# STM32WB55_CM4 register map
File version: 2.0
CPU: CM4 r0p1, little endian, MPU, FPU, 4 interrupt priority bits
Registers are 32-bit, read-write, reset 0x0 unless marked. A register's access mark holds for its fields unless they carry their own. Offsets are from the block's base; [hi:lo] are bit positions; {n}, {i} and the like mark numbered series.

## CRS — Clock recovery system
Base 0x40006000
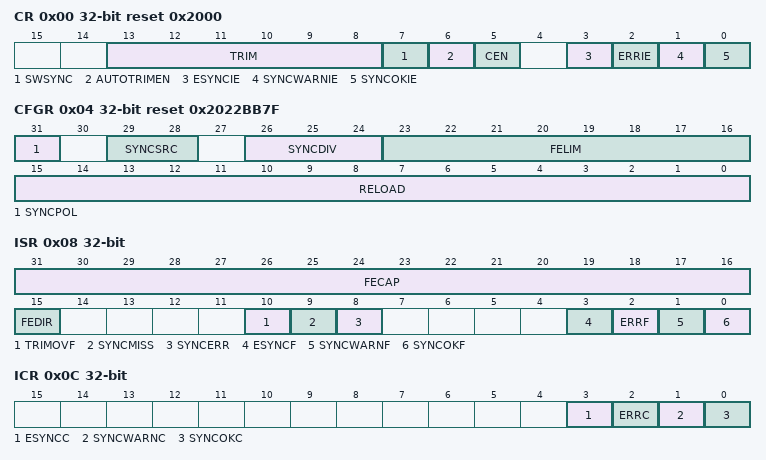
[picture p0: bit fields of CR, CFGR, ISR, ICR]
0x00 CR reset 0x2000 — CRS control register
  [13:8] TRIM — HSI48 oscillator smooth trimming
  [7] SWSYNC — Automatic trimming enable
  [6] AUTOTRIMEN — Automatic trimming enable
  [5] CEN — Frequency error counter enable
  [3] ESYNCIE — Expected SYNC interrupt enable
  [2] ERRIE — Synchronization or trimming error interrupt enable
  [1] SYNCWARNIE — SYNC warning interrupt enable
  [0] SYNCOKIE — SYNC event OK interrupt enable
0x04 CFGR reset 0x2022BB7F — CRS configuration register
  [31] SYNCPOL — SYNC polarity selection
  [29:28] SYNCSRC — SYNC signal source selection
  [26:24] SYNCDIV
  [23:16] FELIM — Frequency error limit
  [15:0] RELOAD — Counter reload value
0x08 ISR ro — CRS interrupt and status register
  [31:16] FECAP — Frequency error capture
  [15] FEDIR — Frequency error direction
  [10] TRIMOVF — Trimming overflow or underflow
  [9] SYNCMISS — SYNC missed
  [8] SYNCERR — SYNC error
  [3] ESYNCF — Expected SYNC flag
  [2] ERRF — Error flag
  [1] SYNCWARNF — SYNC warning flag
  [0] SYNCOKF — SYNC event OK flag
0x0C ICR — CRS interrupt flag clear register
  [3] ESYNCC — Expected SYNC clear flag
  [2] ERRC — Error clear flag
  [1] SYNCWARNC — warning clear flag
  [0] SYNCOKC — SYNC event OK clear flag

## USB — Universal serial bus full-speed device interface
Base 0x40006800
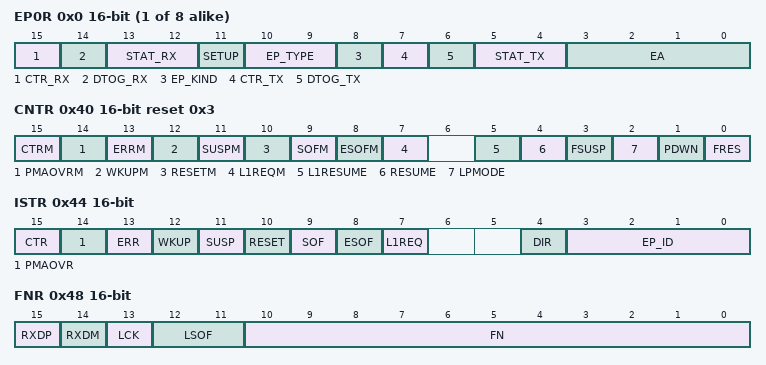
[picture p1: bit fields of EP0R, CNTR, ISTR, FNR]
{0x0+4i} EP{i}R 16-bit (i=0..7) — endpoint {i} register
  [15] CTR_RX — Correct transfer for reception
  [14] DTOG_RX — Data Toggle, for reception transfers
  [13:12] STAT_RX — Status bits, for reception transfers
  [11] SETUP — Setup transaction completed
  [10:9] EP_TYPE — Endpoint type
  [8] EP_KIND — Endpoint kind
  [7] CTR_TX — Correct Transfer for transmission
  [6] DTOG_TX — Data Toggle, for transmission transfers
  [5:4] STAT_TX — Status bits, for transmission transfers
  [3:0] EA — Endpoint address
0x40 CNTR 16-bit reset 0x3 — control register
  [15] CTRM — Correct transfer interrupt mask
  [14] PMAOVRM — Packet memory area over / underrun interrupt mask
  [13] ERRM — Error interrupt mask
  [12] WKUPM — Wakeup interrupt mask
  [11] SUSPM — Suspend mode interrupt mask
  [10] RESETM — USB reset interrupt mask
  [9] SOFM — Start of frame interrupt mask
  [8] ESOFM — Expected start of frame interrupt mask
  [7] L1REQM — LPM L1 state request interrupt mask
  [5] L1RESUME — LPM L1 Resume request
  [4] RESUME — Resume request
  [3] FSUSP — Force suspend
  [2] LPMODE — Low-power mode
  [1] PDWN — Power down
  [0] FRES — Force USB Reset
0x44 ISTR 16-bit access per field — interrupt status register
  [15] CTR ro — Correct transfer
  [14] PMAOVR rw — Packet memory area over / underrun
  [13] ERR rw — Error
  [12] WKUP rw — Wakeup
  [11] SUSP rw — Suspend mode request
  [10] RESET rw — reset request
  [9] SOF rw — start of frame
  [8] ESOF rw — Expected start frame
  [7] L1REQ rw — LPM L1 state request
  [4] DIR ro — Direction of transaction
  [3:0] EP_ID ro — Endpoint Identifier
0x48 FNR 16-bit ro — frame number register
  [15] RXDP — Receive data + line status
  [14] RXDM — Receive data - line status
  [13] LCK — Locked
  [12:11] LSOF — Lost SOF
  [10:0] FN — Frame number
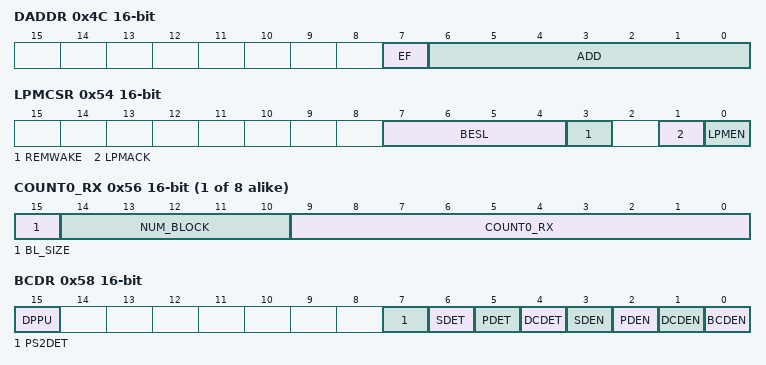
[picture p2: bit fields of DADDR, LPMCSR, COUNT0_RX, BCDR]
0x4C DADDR 16-bit — device address
  [7] EF — Enable function
  [6:0] ADD — Device address
0x50 BTABLE 16-bit — Buffer table address
  [15:3] BTABLE — Buffer table
{0x52+8i} COUNT{i}_TX 16-bit (i=0..7) — Transmission byte count 0
  [9:0] COUNT{i}_TX — Transmission byte count
{0x54+8i} ADDR{i}_RX 16-bit (i=0..7) — Reception buffer address 0
  [15:1] ADDR{i}_RX — Reception buffer address
0x54 LPMCSR 16-bit access per field (alternate view of ADDR0_RX) — control and status register
  [7:4] BESL ro — BESL value
  [3] REMWAKE rw — RemoteWake value
  [1] LPMACK rw — LPM Token acknowledge enable
  [0] LPMEN rw — LPM support enable
{0x56+8i} COUNT{i}_RX 16-bit access per field (i=0..7) — Reception byte count 0
  [15] BL_SIZE rw — Block size
  [14:10] NUM_BLOCK rw — Number of blocks
  [9:0] COUNT{i}_RX ro — Reception byte count
0x58 BCDR 16-bit access per field — Battery charging detector(
  [15] DPPU rw — DP pull-up control
  [7] PS2DET ro — DM pull-up detection status
  [6] SDET ro — Secondary detection (SD) status
  [5] PDET ro — Primary detection (PD) status
  [4] DCDET ro — Data contact detection (DCD) status
  [3] SDEN rw — Secondary detection (SD) mode enable
  [2] PDEN rw — Primary detection (PD) mode enable
  [1] DCDEN rw — Data contact detection (DCD) mode enable
  [0] BCDEN rw — Battery charging detector (BCD) enable

## SysTick — System timer
Base 0xE000E010
0x00 CSR access not given — SysTick Control and Status Register
0x04 RVR access not given — SysTick Reload Value Register
0x08 CVR access not given — SysTick Current Value Register
0x0C CALIB ro — SysTick Calibration Value Register

## NVIC — Nested Vectored Interrupt Controller
Base 0xE000E100
{0x0+4i} ISER{i} (i=0..7) — Interrupt Set-Enable Register
{0x80+4i} ICER{i} (i=0..7) — Interrupt Clear-Enable Register
{0x100+4i} ISPR{i} (i=0..7) — Interrupt Set-Pending Register
{0x180+4i} ICPR{i} (i=0..7) — Interrupt Clear-Pending Register
{0x200+4i} IABR{i} (i=0..7) ro — Interrupt Active Bit Register
{0x300+4i} IPR{i} (i=0..59) — Interrupt Priority Register

## SCB — System Control Block
Base 0xE000ED00
0x00 CPUID ro — CPUID Base Register
0x04 ICSR — Interrupt Control and State Register
0x08 VTOR — Vector Table Offset Register
0x0C AIRCR — Application Interrupt and Reset Control Register
0x10 SCR — System Control Register
0x14 CCR — Configuration and Control Register
{0x14+4i} SHPR{i} (i=1..3) — System Handler Priority Register {i}
0x24 SHCSR — System Handler Control and State Register
0x28 CFSR — Configurable Fault Status Register
0x2C HFSR — HardFault Status Register
0x30 DFSR — Debug Fault Status Register
0x34 MMFAR — MemManage Fault Address Register
0x38 BFAR — BusFault Address Register

## Notices in the file
Copyright (c) 2023 STMicroelectronics.
SPDX-License-Identifier: Apache-2.0
Licensed under the Apache License, Version 2.0 (the "License");
you may not use this file except in compliance with the License.
You may obtain a copy of the License at
http://www.apache.org/licenses/LICENSE-2.0
Unless required by applicable law or agreed to in writing, software
distributed under the License is distributed on an "AS IS" BASIS,
WITHOUT WARRANTIES OR CONDITIONS OF ANY KIND, either express or implied.
See the License for the specific language governing permissions and
limitations under the License.
